# MINI_UART register map
File version: 1
BCM2711 auxiliary mini UART (UART1)
Registers are read-write, no defined reset value unless marked. A register's access mark holds for its fields unless they carry their own. Offsets are from the block's base; lines under a group give offsets from that group; [hi:lo] are bit positions; {n}, {i} and the like mark numbered series; 'fields as' and 'values as' point back to an identical list; <NAME> marks a mode.

## Memory map
0x00000000 MINI_UART size 0x40

## MINI_UART
Base 0x00000000
0x00 IO read-modifies — AUX_MU_IO_REG: a read takes the next byte of the receive FIFO, a write puts a byte in the transmit FIFO
  [7:0] DATA
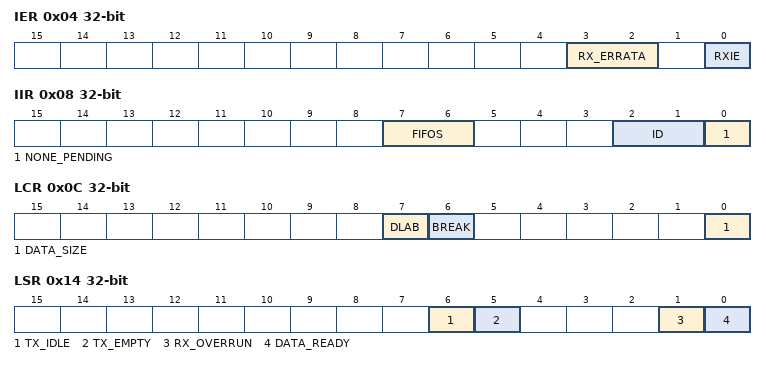
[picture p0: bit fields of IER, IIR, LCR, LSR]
0x04 IER — AUX_MU_IER_REG: interrupt enables
  [3:2] RX_ERRATA — Unverified: the PDF gives bits 7:2 no meaning, and the driver sets both with RXIE in the belief that the silicon's receive interrupt needs them (the 8250 names these positions ERLS and EMSC, ns16550.h IER_ERLS and IER_EMSC)
  [0] RXIE — Interrupt while the receive FIFO holds a byte. Unverified: bit 0 is the 8250's receive enable (ns16550.h IER_ERXRDY); the PDF's table prints the receive enable at bit 1 and the transmit enable at bit 0
0x08 IIR — AUX_MU_IIR_REG: the pending interrupt; writing with bit 1 set clears the receive FIFO, with bit 2 set the transmit FIFO, so it is written whole, never read back and rewritten
  [7:6] FIFOS — Both FIFOs always enabled, reads 3
  [2:1] ID — 1 transmit FIFO empty, 2 receive FIFO holds a byte
  [0] NONE_PENDING — 0 while an interrupt is pending
0x0C LCR — AUX_MU_LCR_REG: line control
  [7] DLAB — Give the first two registers to the baud rate's bytes
  [6] BREAK — Hold the transmit line low
  [0] DATA_SIZE — Set for eight-bit characters, clear for seven; bits 5:1 are reserved
0x10 MCR — AUX_MU_MCR_REG: modem control
  [1] RTS — Drive the RTS line low
0x14 LSR ro — AUX_MU_LSR_REG: line status
  [6] TX_IDLE — The transmit FIFO is empty and the transmitter idle
  [5] TX_EMPTY — The transmit FIFO can take at least one byte
  [1] RX_OVERRUN — A byte arrived to a full receive FIFO; cleared by the read
  [0] DATA_READY — The receive FIFO holds at least one byte
0x18 MSR ro — AUX_MU_MSR_REG: modem status
  [4] CTS — The CTS line's state, inverted
0x1C SCRATCH — AUX_MU_SCRATCH: a byte of storage
  [7:0] VALUE
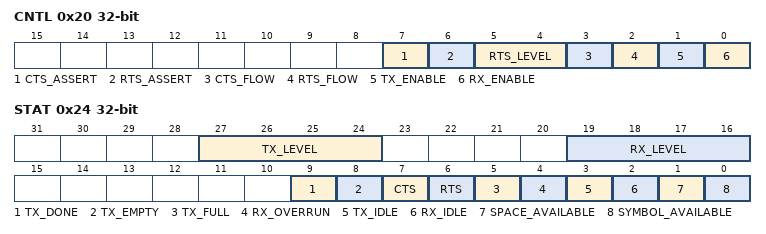
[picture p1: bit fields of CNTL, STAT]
0x20 CNTL — AUX_MU_CNTL_REG: receiver, transmitter and flow control
  [7] CTS_ASSERT, [6] RTS_ASSERT, [5:4] RTS_LEVEL, [3] CTS_FLOW, [2] RTS_FLOW, [1] TX_ENABLE, [0] RX_ENABLE
0x24 STAT ro — AUX_MU_STAT_REG: the FIFOs' and lines' state
  [27:24] TX_LEVEL, [19:16] RX_LEVEL, [9] TX_DONE, [8] TX_EMPTY, [7] CTS, [6] RTS, [5] TX_FULL, [4] RX_OVERRUN, [3] TX_IDLE, [2] RX_IDLE, [1] SPACE_AVAILABLE, [0] SYMBOL_AVAILABLE
0x28 BAUD — AUX_MU_BAUD_REG: the baud divisor, system clock / (8 * (BAUD + 1))
  [15:0] DIVISOR

## Notices in the file
Copyright (c) 2026, Stanislav Sedov <stas@deglitch.com>
SPDX-License-Identifier: BSD-2-Clause
